# CY8C5868AXI_LP035 register map
File version: 0.1
CY8C58LP
Registers are 8-bit, read-write, no defined reset value unless marked. A register's access mark holds for its fields unless they carry their own. Offsets are from the block's base; lines under a group give offsets from that group; [hi:lo] are bit positions; {n}, {i} and the like mark numbered series; 'fields as' and 'values as' point back to an identical list; <NAME> marks a mode.

## Memory map
0x00000000 USBUART — USBFS
0x00000000 Tone_F
0x00000000 Tone_D
0x00000000 CapSense
0x00000000 CapSense_IdacCH0
0x00000000 CapSense_CompCH0
0x00000000 PWM

## Tone_F
Base 0x00000000
0x4000652A Tone_F_COMPARE_Reg 16-bit — UDB.D0 - Assigned Compare Value
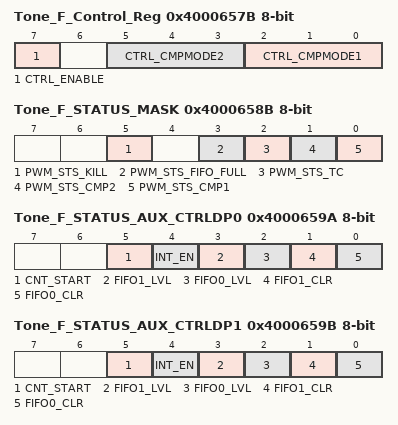
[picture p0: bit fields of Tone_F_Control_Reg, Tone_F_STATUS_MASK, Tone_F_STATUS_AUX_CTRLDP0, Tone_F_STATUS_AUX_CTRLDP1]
0x4000657B Tone_F_Control_Reg — UDB Control Register - Assigned Control Register Value
  [7] CTRL_ENABLE — Enable the PWM
  [5:3] CTRL_CMPMODE2 — Compare mode 2
  [2:0] CTRL_CMPMODE1 — Compare mode 1
0x4000658B Tone_F_STATUS_MASK — UDB Status bits Interrupt Mask Enable Register
  [5] PWM_STS_KILL ro — Enables the Interrupt on Kill
  [3] PWM_STS_FIFO_FULL ro — FIFO Full Status Mask
  [2] PWM_STS_TC ro — Enables the Interrupt on Terminal Count
  [1] PWM_STS_CMP2 ro — Enables the Interrupt on Compare 2
  [0] PWM_STS_CMP1 ro — Enables the Interrupt on Compare 1
0x4000659A Tone_F_STATUS_AUX_CTRLDP0 — UDB Auxilliary Control Register
  [5] CNT_START — FIFO0 clear
    0=E_CNT_START0 (Disable counter); 1=E_CNT_START1 (Enable counter)
  [4] INT_EN
    0=E_INT_EN0 (Interrupt disabled); 1=E_INT_EN1 (Interrupt enabled)
  [3] FIFO1_LVL — FIFO level
    0=E_FIFO_LVL_0 (FIFO LVL: input mode: FIFO not full; output mode: FIFO not empty); 1=E_FIFO_LVL_1 (FIFO LVL: input mode: FIFO at least 1/2 empty; output mode: FIFO at least 1/2 full)
  [2] FIFO0_LVL — FIFO level
    values as FIFO1_LVL
  [1] FIFO1_CLR — FIFO1 clear
    0=E_FIFO_CLR_0 (Normal FIFO operation); 1=E_FIFO_CLR_1 (Clear FIFO state)
  [0] FIFO0_CLR — FIFO0 clear
    values as FIFO1_CLR
0x4000659B Tone_F_STATUS_AUX_CTRLDP1 — UDB Auxilliary Control Register
  fields as Tone_F_STATUS_AUX_CTRLDP0

## Tone_D
Base 0x00000000
0x40006406 Tone_D_COUNTER 16-bit — UDB.A0 - Current Counter Value
0x40006426 Tone_D_PERIOD 16-bit — UDB.D0 - Assigned Period
0x40006436 Tone_D_COMPARE 16-bit — UDB.D1 - Assigned Compare Value
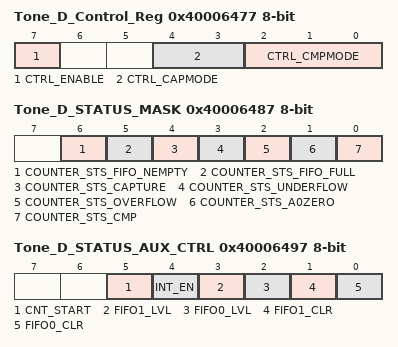
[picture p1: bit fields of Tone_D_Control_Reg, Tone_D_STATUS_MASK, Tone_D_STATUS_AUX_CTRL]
0x40006477 Tone_D_Control_Reg — UDB Control Register - Assigned Control Register Value
  [7] CTRL_ENABLE — Enable Counter
  [4:3] CTRL_CAPMODE — Capture mode
  [2:0] CTRL_CMPMODE — Compare mode
0x40006487 Tone_D_STATUS_MASK — UDB Status bits Interrupt Mask Enable Register
  [6] COUNTER_STS_FIFO_NEMPTY — FIFO Not Empty Status
  [5] COUNTER_STS_FIFO_FULL — FIFO Full Status
  [4] COUNTER_STS_CAPTURE — Capture Status
  [3] COUNTER_STS_UNDERFLOW — Underflow status
  [2] COUNTER_STS_OVERFLOW — Overflow status
  [1] COUNTER_STS_A0ZERO — A0 Zero ouput status
  [0] COUNTER_STS_CMP — Compare output status
0x40006497 Tone_D_STATUS_AUX_CTRL — UDB Auxilliary Control Register
  [5] CNT_START — FIFO0 clear
    0=E_CNT_START0 (Disable counter); 1=E_CNT_START1 (Enable counter)
  [4] INT_EN
    0=E_INT_EN0 (Interrupt disabled); 1=E_INT_EN1 (Interrupt enabled)
  [3] FIFO1_LVL — FIFO level
    0=E_FIFO_LVL_0 (FIFO LVL: input mode: FIFO not full; output mode: FIFO not empty); 1=E_FIFO_LVL_1 (FIFO LVL: input mode: FIFO at least 1/2 empty; output mode: FIFO at least 1/2 full)
  [2] FIFO0_LVL — FIFO level
    values as FIFO1_LVL
  [1] FIFO1_CLR — FIFO1 clear
    0=E_FIFO_CLR_0 (Normal FIFO operation); 1=E_FIFO_CLR_1 (Clear FIFO state)
  [0] FIFO0_CLR — FIFO0 clear
    values as FIFO1_CLR

## CapSense
Base 0x00000000
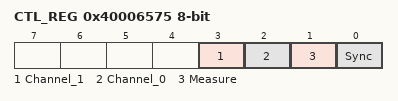
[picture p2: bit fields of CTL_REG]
0x40006575 CTL_REG — CapSense Control Register
  [3] Channel_1 ro — Channel 1 Enable
    0=Disabled (Channel 1 scanning is disabled); 1=Enabled (Channel 1 scanning is enabled)
  [2] Channel_0 ro — Channel 0 Enable
    0=Disabled (Channel 0 scanning is disabled); 1=Enabled (Channel 0 scanning is enabled)
  [1] Measure ro — Measurement Enable
    0=Disabled (Capacitance measurement is disabled); 1=Enabled (Capacitance measurement is enabled)
  [0] Sync ro — Reset Digital and Pre-Charge Clocks
    0=Disabled (Clocks are in the reset state); 1=Enabled (Clocks are enabled)
0x40006594 ScanSpeed_CTL_REG — CapSense Clock Prescaler Control Register
  [3] Counter ro — Clock Prescaler Enable
    0=Disabled (Prescaler counter is disabled); 1=Enabled (Prescaler counter is enabled)
